AUTOSAR XML (schema 4-2-2)
package /ASW_CORE3
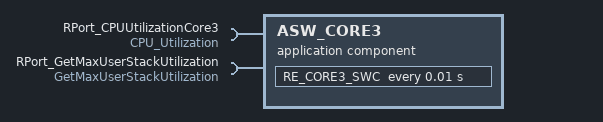
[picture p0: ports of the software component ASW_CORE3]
  application sw component type ASW_CORE3
    require port RPort_CPUUtilizationCore3: required-interface=CPU_Utilization
    require port RPort_GetMaxUserStackUtilization: required-interface=GetMaxUserStackUtilization
    behavior SwcInternalBehavior
      timing event TimingEvent_0: start-on-event=RE_CORE3_SWC, period=0.01
      runnable RE_CORE3_SWC: symbol=RE_CORE3_SWC_func
        sync call SynchronousServerCallPoint_0: operation=RPort_CPUUtilizationCore3.CPU_Utilization
        sync call SynchronousServerCallPoint_1: operation=RPort_GetMaxUserStackUtilization.GetMaxUserStackUtilization
